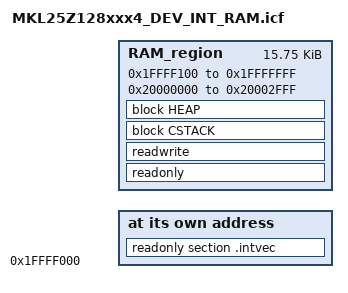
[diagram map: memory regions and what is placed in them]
/*###ICF### Section handled by ICF editor, don't touch! ****/
/*-Editor annotation file-*/
/* IcfEditorFile="$TOOLKIT_DIR$\config\ide\IcfEditor\a_v1_0.xml" */
/*-Memory Regions-*/

define symbol __ICFEDIT_region_RAM_start__   = 0x1ffff000+0x100;
define symbol __ICFEDIT_region_RAM_end__     = 0x1fffffff;
/*-Sizes-*/
define symbol __ICFEDIT_size_cstack__   = 0x0200;
define symbol __ICFEDIT_size_heap__     = 0x0000;
/**** End of ICF editor section. ###ICF###*/
/*-Specials-*/
define symbol __ICFEDIT_intvec_start__ = 0x1ffff000;
define symbol __region_RAM2_start__ 		= 0x20000000;
define symbol __region_RAM2_end__ 			= 0x20002fff;

define memory mem with size = 4G;
define region RAM_region = mem:[from __ICFEDIT_region_RAM_start__ to __ICFEDIT_region_RAM_end__] | mem:[from __region_RAM2_start__ to __region_RAM2_end__];

define block CSTACK    with alignment = 8, size = __ICFEDIT_size_cstack__   { };
define block HEAP      with alignment = 8, size = __ICFEDIT_size_heap__     { };

initialize by copy { readwrite };
do not initialize  { section .noinit };

place at address mem:__ICFEDIT_intvec_start__ { readonly section .intvec };

place in RAM_region   { readonly };
place in RAM_region   { readwrite,
                        block CSTACK, block HEAP };
